# SAMA7D65D2GN8 register map
Vendor: Microchip Technology; Series: SAMA7D6; File version: 0
Registers are 32-bit, read-write, reset 0x0 unless marked. A register's access mark holds for its fields unless they carry their own. Offsets are from the block's base; [hi:lo] are bit positions; lines under a group give offsets from that group; {n}, {i} and the like mark numbered series; 'fields as' and 'values as' point back to an identical list.

## XDMAC0 — Extensible DMA Controller
Base 0xE1610000; register names take the prefix XDMAC_
Same registers: XDMAC2 0xE1200000, XDMAC1 0xE1614000
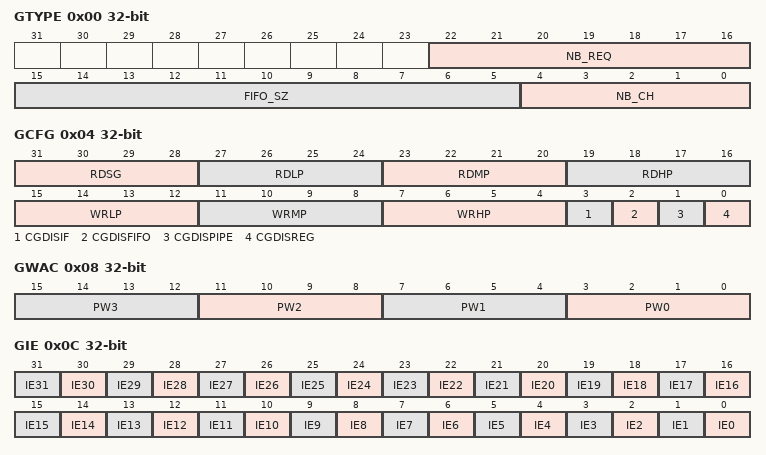
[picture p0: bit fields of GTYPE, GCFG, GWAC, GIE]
0x00 GTYPE ro — Global Type Register
  [22:16] NB_REQ — Number of Peripheral Requests Minus One
  [15:5] FIFO_SZ — Number of Bytes
  [4:0] NB_CH — Number of Channels Minus One
0x04 GCFG — Global Configuration Register
  [31:28] RDSG — Read Queue Scatter Gather Outstanding Limit
  [27:24] RDLP — Read Queue Low Priority Outstanding Limit
  [23:20] RDMP — Read Queue Medium Priority Outstanding Limit
  [19:16] RDHP — Read Queue High Priority Outstanding Limit
  [15:12] WRLP — Write Queue Low Priority Outstanding Limit
  [11:8] WRMP — Write Queue Medium Priority Outstanding Limit
  [7:4] WRHP — Write Queue High Priority Outstanding Limit
  [3] CGDISIF — Bus Interface Clock Gating Disable
    0=The automatic clock gating is enabled for the system bus interface; 1=The automatic clock gating is disabled for the system bus interface
  [2] CGDISFIFO — FIFO Clock Gating Disable
    0=The automatic clock gating is enabled for the main FIFO; 1=The automatic clock gating is disabled for the main FIFO
  [1] CGDISPIPE — Pipeline Clock Gating Disable
    0=The automatic clock gating is enabled for the main pipeline; 1=The automatic clock gating is disabled for the main pipeline
  [0] CGDISREG — Configuration Registers Clock Gating Disable
    0=The automatic clock gating is enabled for the configuration registers; 1=The automatic clock gating is disabled for the configuration registers
0x08 GWAC — Global Weighted Arbiter Configuration Register
  [4n+3:4n] PW{n} (n=0..3) — Pool Weight {n}
0x0C GIE wo — Global Interrupt Enable Register
  [all] fields
    0=This bit has no effect. The Channel x Interrupt Mask bit (XDMAC_GIM.IMx) is not modified.; 1=The corresponding mask bit is set. The XDMAC Channel x Interrupt Status register (XDMAC_GIS) can generate an interrupt.
  [n] IE{n} (n=0..31) — XDMAC Channel {n} Interrupt Enable
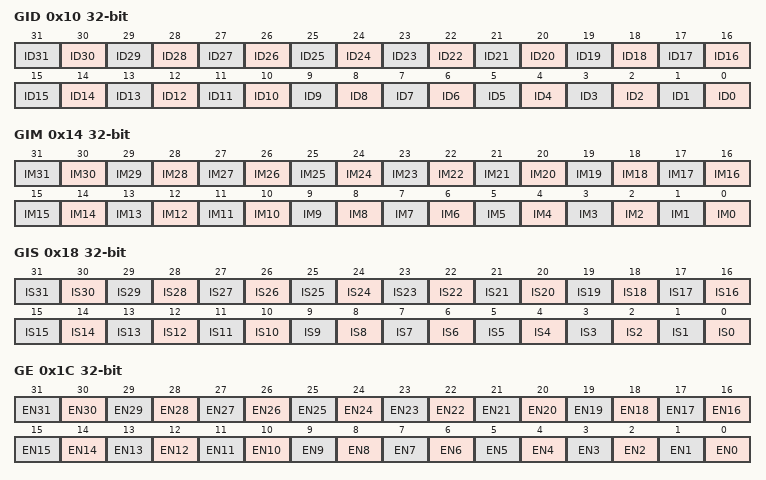
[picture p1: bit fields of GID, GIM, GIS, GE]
0x10 GID wo — Global Interrupt Disable Register
  [all] fields
    0=This bit has no effect. The Channel x Interrupt Mask bit (XDMAC_GIM.IMx) is not modified.; 1=The corresponding mask bit is reset. The Channel x Interrupt Status register interrupt (XDMAC_GIS) is masked.
  [n] ID{n} (n=0..31) — XDMAC Channel {n} Interrupt Disable
0x14 GIM ro — Global Interrupt Mask Register
  [all] fields
    0=This bit indicates that the channel x interrupt source is masked. The interrupt line is not raised.; 1=This bit indicates that the channel x interrupt source is unmasked
  [n] IM{n} (n=0..31) — XDMAC Channel {n} Interrupt Mask
0x18 GIS ro — Global Interrupt Status Register
  [all] fields
    0=This bit indicates that either the interrupt source is masked at the channel level or no interrupt is pending for channel x; 1=This bit indicates that an interrupt is pending for the channel x
  [n] IS{n} (n=0..31) — XDMAC Channel {n} Interrupt Status
0x1C GE wo — Global Channel Enable Register
  [all] fields
    0=This bit has no effect; 1=Enables channel x. This operation is permitted if the Channel x Status bit (XDMAC_GS.STx) was read as 0.
  [n] EN{n} (n=0..31) — XDMAC Channel {n} Enable
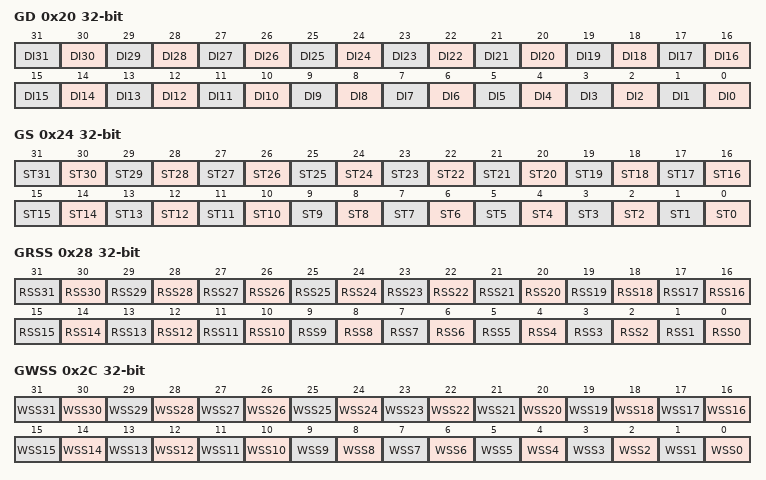
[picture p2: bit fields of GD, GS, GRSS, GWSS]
0x20 GD wo — Global Channel Disable Register
  [all] fields
    0=This bit has no effect; 1=Disables channel x
  [n] DI{n} (n=0..31) — XDMAC Channel {n} Disable
0x24 GS ro — Global Channel Status Register
  [all] fields
    0=This bit indicates that the channel x is disabled; 1=This bit indicates that the channel x is enabled. If a channel disable request is issued, this bit remains asserted until pending transaction is completed.
  [n] ST{n} (n=0..31) — XDMAC Channel {n} Status
0x28 GRSS ro — Global Channel Read Suspend Status Register
  [all] fields
    0=The read channel is not suspended; 1=The source requests for channel x are no longer serviced by the system scheduler
  [n] RSS{n} (n=0..31) — XDMAC Channel {n} Read Suspend Status
0x2C GWSS ro — Global Channel Write Suspend Status Register
  [all] fields
    0=The write channel is not suspended; 1=The source requests for channel x are no longer serviced by the system scheduler
  [n] WSS{n} (n=0..31) — XDMAC Channel {n} Write Suspend Status
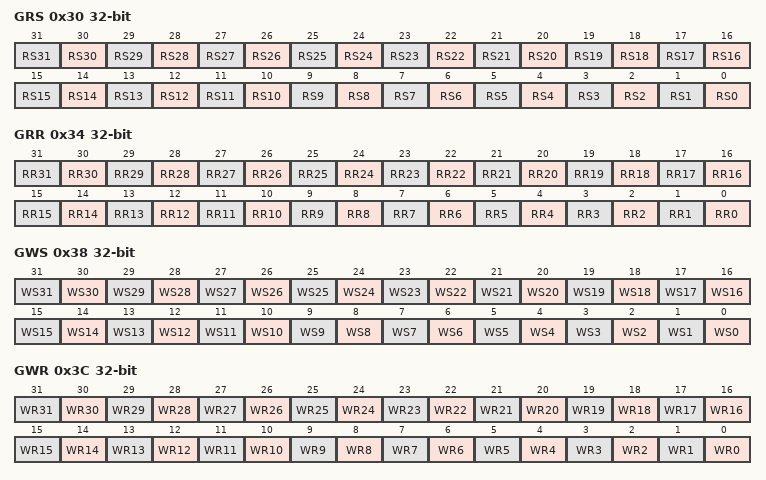
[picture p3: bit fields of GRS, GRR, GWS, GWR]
0x30 GRS wo — Global Channel Read Suspend Register
  [all] fields
    0=No effect; 1=The source requests for channel x are no longer serviced by the system scheduler
  [n] RS{n} (n=0..31) — XDMAC Channel {n} Read Suspend
0x34 GRR wo — Global Channel Read Resume Register
  [all] fields
    0=No effect; 1=The source requests for channel x are serviced by the system scheduler
  [n] RR{n} (n=0..31) — XDMAC Channel {n} Read Resume
0x38 GWS wo — Global Channel Write Suspend Register
  [all] fields
    0=The write channel is not suspended; 1=Destination requests are no longer routed to the scheduler
  [n] WS{n} (n=0..31) — XDMAC Channel {n} Write Suspend
0x3C GWR wo — Global Channel Write Resume Register
  [all] fields
    0=No effect; 1=Destination requests are serviced and routed to the scheduler
  [n] WR{n} (n=0..31) — XDMAC Channel {n} Write Resume
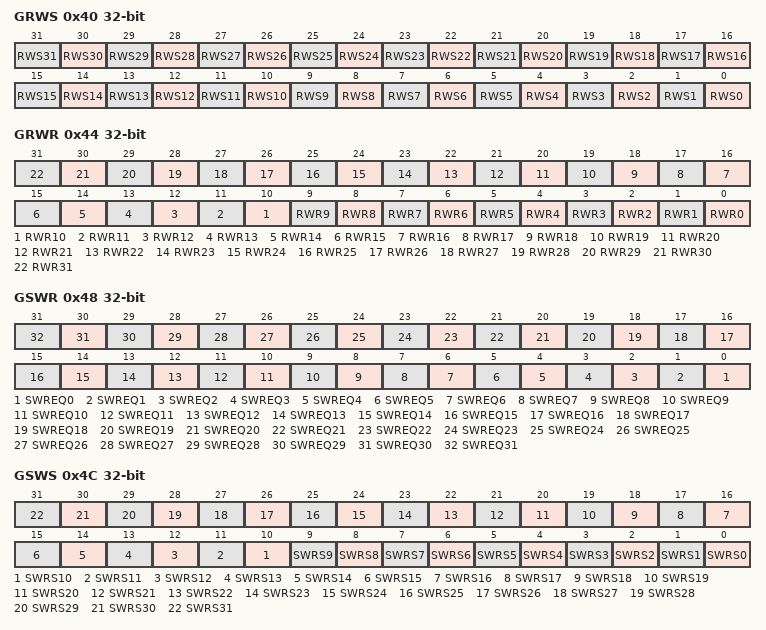
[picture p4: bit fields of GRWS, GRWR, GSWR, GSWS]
0x40 GRWS wo — Global Channel Read Write Suspend Register
  [all] fields
    0=No effect; 1=Read and write requests are suspended
  [n] RWS{n} (n=0..31) — XDMAC Channel {n} Read Write Suspend
0x44 GRWR wo — Global Channel Read Write Resume Register
  [all] fields
    0=No effect; 1=Read and write requests are serviced
  [n] RWR{n} (n=0..31) — XDMAC Channel {n} Read Write Resume
0x48 GSWR wo — Global Channel Software Request Register
  [all] fields
    0=No effect; 1=Requests a DMA transfer for channel x
  [n] SWREQ{n} (n=0..31) — XDMAC Channel {n} Software Request
0x4C GSWS ro — Global Channel Software Request Status Register
  [all] fields
    0=Channel x source request is serviced; 1=Channel x source request is pending
  [n] SWRS{n} (n=0..31) — XDMAC Channel {n} Software Request Status
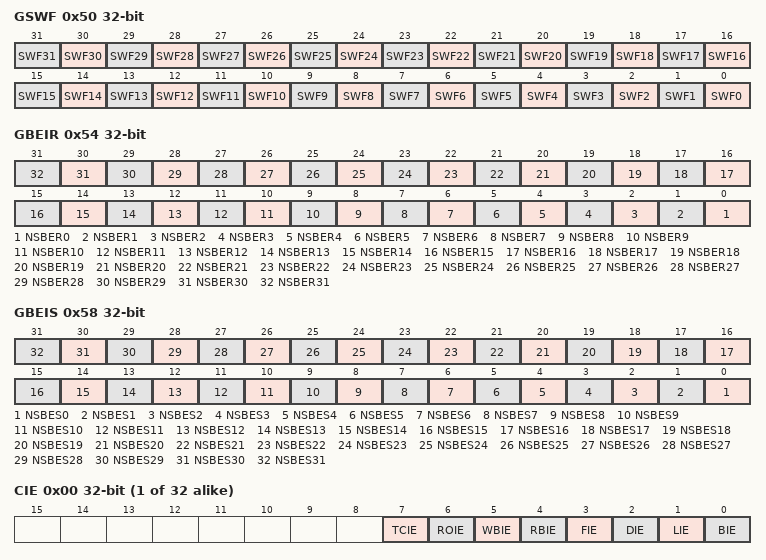
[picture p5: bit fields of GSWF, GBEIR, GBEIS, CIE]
0x50 GSWF — Global Channel Software Flush Request Register
  [all] fields
    0=No effect; 1=Requests a DMA transfer flush for channel x. This bit is only relevant when the transfer is source peripheral synchronized.
  [n] SWF{n} (n=0..31) — XDMAC Channel {n} Software Flush Request
0x54 GBEIR — Global Bus Error Interrupt Routing Register
  [all] fields
    0=Non-secure channel x bus errors are flagged in the Channel x Interrupt Status register and they can only set the non-secure interrupt line; 1=Non-secure channel x bus errors are flagged in the secure Global Bus Error Interrupt Status register x bit and they only set the secure Interrupt line
  [n] NSBER{n} (n=0..31) — XDMAC Channel {n} Non-Secure Bus Error Routing
0x58 GBEIS ro — Global Bus Error Interrupt Status Register
  [all] fields
    0=No non-secure bus error occurred on channel x since the last read of this register or the Bus Error events are not routed to the secure interrupt in the XDMAC_GBEIR.x bit; 1=A non-secure bus error occurred on channel x since the last read of this register and the Bus Error events are routed to the secure interrupt in the XDMAC_GBEIR.x bit
  [n] NSBES{n} (n=0..31) — XDMAC Channel {n} Non-Secure Bus Error Status
{0x60+0x40*i} XDMAC_CHID[{i}] (i=0..31) group
  0x00 CIE wo — Channel Interrupt Enable Register
    [7] TCIE — Transfer Count Overflow Error Interrupt Enable
      0=No effect; 1=Enables transfer count overflow error interrupt
    [6] ROIE — Request Overflow Error Interrupt Enable
      0=No effect; 1=Enables request overflow error interrupt
    [5] WBIE — Write Bus Error Interrupt Enable
      0=No effect; 1=Enables write bus error interrupt
    [4] RBIE — Read Bus Error Interrupt Enable
      0=No effect; 1=Enables read bus error interrupt
    [3] FIE — End of Flush Interrupt Enable
      0=No effect; 1=Enables end of flush interrupt
    [2] DIE — End of Disable Interrupt Enable
      0=No effect; 1=Enables end of disable interrupt
    [1] LIE — End of Linked List Interrupt Enable
      0=No effect; 1=Enables end of linked list interrupt
    [0] BIE — End of Block Interrupt Enable
      0=No effect; 1=Enables end of block interrupt
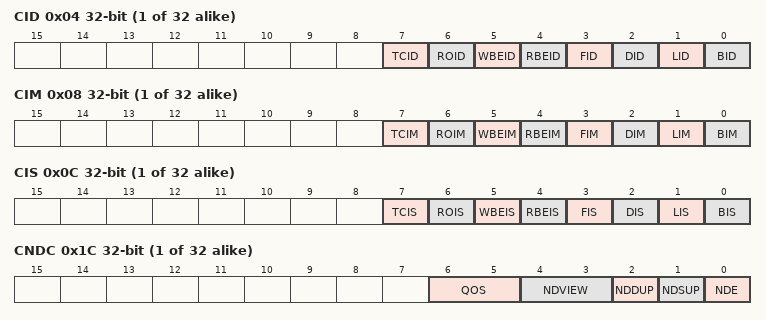
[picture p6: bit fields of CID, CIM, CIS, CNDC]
  0x04 CID wo — Channel Interrupt Disable Register
    [7] TCID — Transfer Count Overflow Error Interrupt Disable
      0=No effect; 1=Disables transfer count overflow error interrupt
    [6] ROID — Request Overflow Error Interrupt Disable
      0=No effect; 1=Disables request overflow error interrupt
    [5] WBEID — Write Bus Error Interrupt Disable
      0=No effect; 1=Disables bus error interrupt
    [4] RBEID — Read Bus Error Interrupt Disable
      0=No effect; 1=Disables bus error interrupt
    [3] FID — End of Flush Interrupt Disable
      0=No effect; 1=Disables end of flush interrupt
    [2] DID — End of Disable Interrupt Disable
      0=No effect; 1=Disables end of disable interrupt
    [1] LID — End of Linked List Interrupt Disable
      0=No effect; 1=Disables end of linked list interrupt
    [0] BID — End of Block Interrupt Disable
      0=No effect; 1=Disables end of block interrupt
  0x08 CIM ro — Channel Interrupt Mask Register
    [7] TCIM — Transfer Count Overflow Error Interrupt Mask
      0=Transfer count overflow interrupt is masked; 1=Transfer count overflow interrupt is activated
    [6] ROIM — Request Overflow Error Interrupt Mask
      0=Request overflow interrupt is masked; 1=Request overflow interrupt is activated
    [5] WBEIM — Write Bus Error Interrupt Mask
      0=Bus error interrupt is masked; 1=Bus error interrupt is activated
    [4] RBEIM — Read Bus Error Interrupt Mask
      values as WBEIM
    [3] FIM — End of Flush Interrupt Mask
      0=End of flush interrupt is masked; 1=End of flush interrupt is activated
    [2] DIM — End of Disable Interrupt Mask
      0=End of disable interrupt is masked; 1=End of disable interrupt is activated
    [1] LIM — End of Linked List Interrupt Mask
      0=End of linked list interrupt is masked; 1=End of linked list interrupt is activated
    [0] BIM — End of Block Interrupt Mask
      0=Block interrupt is masked; 1=Block interrupt is activated
  0x0C CIS ro — Channel Interrupt Status Register
    [7] TCIS — Transfer Count Overflow Interrupt Status
      0=Transfer count overflow has not occurred; 1=At least one transfer count overflow has been detected since the last read of the Status register
    [6] ROIS — Request Overflow Error Interrupt Status
      0=Overflow condition has not occurred; 1=Overflow condition has occurred at least once. (This information is only relevant for peripheral synchronized transfers.)
    [5] WBEIS — Write Bus Error Interrupt Status
      0=Write bus error condition has not occurred; 1=At least one bus error has been detected in a write access since the last read of the Status register
    [4] RBEIS — Read Bus Error Interrupt Status
      0=Read bus error condition has not occurred; 1=At least one bus error has been detected in a read access since the last read of the Status register
    [3] FIS — End of Flush Interrupt Status
      0=End of flush condition has not occurred; 1=End of flush condition has occurred since the last read of the Status register
    [2] DIS — End of Disable Interrupt Status
      0=End of disable condition has not occurred; 1=End of disable condition has occurred since the last read of the Status register
    [1] LIS — End of Linked List Interrupt Status
      0=End of linked list condition has not occurred; 1=End of linked list condition has occurred since the last read of the Status register
    [0] BIS — End of Block Interrupt Status
      0=End of block interrupt has not occurred; 1=End of block interrupt has occurred since the last read of the Status register
  0x10 CSA — Channel Source Address Register
    [31:0] SA — Channel Source Address
  0x14 CDA — Channel Destination Address Register
    [31:0] DA — Channel Destination Address
  0x18 CNDA — Channel Next Descriptor Address Register
    [31:2] NDA — Channel Next Descriptor Address
  0x1C CNDC — Channel Next Descriptor Control Register
    [6:5] QOS — Channel Quality Of Service Level
    [4:3] NDVIEW — Channel Next Descriptor View
      {v}=NDV{v} (Next Descriptor View {v}) (v=0..3)
    [2] NDDUP — Channel Next Descriptor Destination Update
      0=DST_PARAMS_UNCHANGED (Destination parameters remain unchanged.); 1=DST_PARAMS_UPDATED (Destination parameters are updated when the descriptor is retrieved.)
    [1] NDSUP — Channel Next Descriptor Source Update
      0=SRC_PARAMS_UNCHANGED (Source parameters remain unchanged.); 1=SRC_PARAMS_UPDATED (Source parameters are updated when the descriptor is retrieved.)
    [0] NDE — Channel Next Descriptor Enable
      0=DSCR_FETCH_DIS (Descriptor fetch is disabled.); 1=DSCR_FETCH_EN (Descriptor fetch is enabled.)
  0x20 CUBC — Channel Microblock Control Register
    [23:0] UBLEN — Channel Microblock Length
  0x24 CBC — Channel Block Control Register
    [11:0] BLEN — Channel Block Length
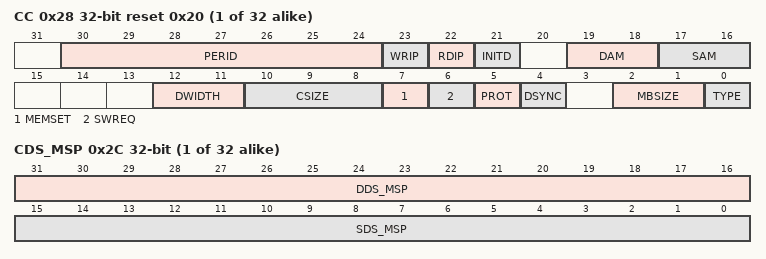
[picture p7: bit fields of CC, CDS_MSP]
  0x28 CC reset 0x20 — Channel Configuration Register
    [30:24] PERID — Channel Peripheral Hardware Request Line Identifier
    [23] WRIP — Write in Progress (this bit is read-only)
      0=DONE (No active write transaction on the bus.); 1=IN_PROGRESS (A write transaction is in progress.)
    [22] RDIP — Read in Progress (this bit is read-only)
      0=DONE (No active read transaction on the bus.); 1=IN_PROGRESS (A read transaction is in progress.)
    [21] INITD — Channel Initialization Done (this bit is read-only)
      0=IN_PROGRESS (Channel initialization is in progress.); 1=TERMINATED (Channel initialization is completed.)
    [19:18] DAM — Channel Destination Addressing Mode
      0=FIXED_AM (The address remains unchanged.); 1=INCREMENTED_AM (The addressing mode is incremented (the increment size is set to the data size).); 2=UBS_AM (The microblock stride is added at the microblock boundary.); 3=UBS_DS_AM (The microblock stride is added at the microblock boundary; the data stride is added at the data boundary.)
    [17:16] SAM — Channel Source Addressing Mode
      0=FIXED_AM (The address remains unchanged.); 1=INCREMENTED_AM (The addressing mode is incremented (the increment size is set to the data size).); 2=UBS_AM (The microblock stride is added at the microblock boundary.); 3=UBS_DS_AM (The microblock stride is added at the microblock boundary, the data stride is added at the data boundary.)
    [12:11] DWIDTH — Channel Data Width
      0=BYTE (The data size is set to 8 bits); 1=HALFWORD (The data size is set to 16 bits); 2=WORD (The data size is set to 32 bits); 3=DWORD (The data size is set to 64 bits)
    [10:8] CSIZE — Channel Chunk Size
      0=CHK_1 (1 data transferred); 1=CHK_2 (2 data transferred); 2=CHK_4 (4 data transferred); 3=CHK_8 (8 data transferred); 4=CHK_16 (16 data transferred)
    [7] MEMSET — Channel Fill Block of Memory
      0=NORMAL_MODE (Memset is not activated.); 1=HW_MODE (Sets the block of memory pointed by DA field to the specified value. This operation is performed on 8-, 16- or 32-bit basis.)
    [6] SWREQ — Channel Software Request Trigger
      0=HWR_CONNECTED (Hardware request line is connected to the peripheral request line.); 1=SWR_CONNECTED (Software request is connected to the peripheral request line.)
    [5] PROT — Channel Protection
      0=SEC (Channel is secured.); 1=UNSEC (Channel is unsecured.)
    [4] DSYNC — Channel Synchronization
      0=PER2MEM (Peripheral-to-memory transfer.); 1=MEM2PER (Memory-to-peripheral transfer)
    [2:1] MBSIZE — Channel Memory Burst Size
      0=SINGLE (The memory burst size is set to one.); 1=FOUR (The memory burst size is set to four.); 2=EIGHT (The memory burst size is set to eight.); 3=SIXTEEN (The memory burst size is set to sixteen.)
    [0] TYPE — Channel Transfer Type
      0=MEM_TRAN (Self-triggered mode (memory-to-memory transfer).); 1=PER_TRAN (Synchronized mode (peripheral-to-memory or memory-to-peripheral transfer).)
  0x2C CDS_MSP — Channel Data Stride Memory Set Pattern
    [31:16] DDS_MSP — Channel Destination Data Stride or Memory Set Pattern
    [15:0] SDS_MSP — Channel Source Data stride or Memory Set Pattern
  0x30 CSUS — Channel Source Microblock Stride
    [23:0] SUBS
  0x34 CDUS — Channel Destination Microblock Stride
    [23:0] DUBS
  0x38 CTCS ro — Channel Transfer Counter Status Register
    [23:0] TC — Channel Transfer Count
      1=Read the XDMAC_CTCSx.TC field to sample the number of bytes received by the XDMA; 2=Perform a software flush of the channel by writing one to the XDMAC_GSWF register. This will push bytes from the internal DMA FIFO to the external memory and return an interrupt when the bytes can be read by the CPU.
